# RE01_1500KB register map
Vendor: Renesas Electronics Corporation; Series: RE01_1500KB; File version: 1.20
CPU: CM0PLUS r0p1, little endian, MPU, no FPU, VTOR, 2 interrupt priority bits
Registers are 8-bit, read-write, reset 0x0 unless marked. A register's access mark holds for its fields unless they carry their own. Offsets are from the block's base; [hi:lo] are bit positions; {n}, {i} and the like mark numbered series.

## PMISC — Miscellaneous Port Control Register
Base 0x40040D00
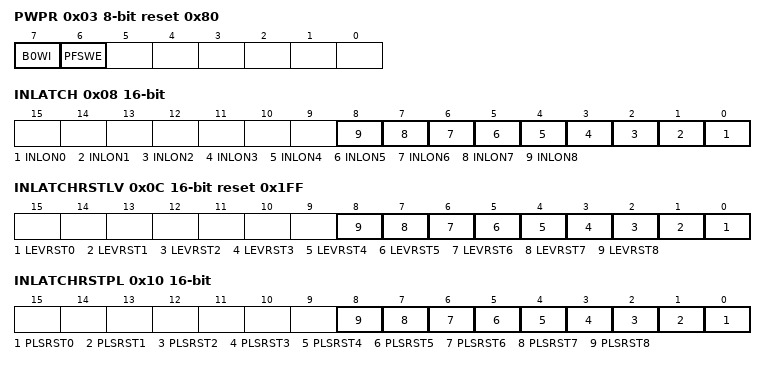
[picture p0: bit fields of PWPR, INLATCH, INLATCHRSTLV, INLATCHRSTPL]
0x03 PWPR reset 0x80 — Write-Protect Register
  [7] B0WI — PFSWE Bit Write Disable
    0=Writing to the PFSWE bit is enabled; 1=Writing to the PFSWE bit is disabled
  [6] PFSWE — PFS Register Write Enable
    0=Writing to the PFS register is disabled; 1=Writing to the PFS register is enabled
0x08 INLATCH 16-bit — Input PAD Latch Control Register
  [n] INLON{n} (n=0..8)
0x0C INLATCHRSTLV 16-bit reset 0x1FF — Input PAD Latch Level Reset Control Register
  [n] LEVRST{n} (n=0..8)
0x10 INLATCHRSTPL 16-bit — Input PAD Latch Pulse Reset Control Register
  [n] PLSRST{n} (n=0..8)

## POE — Port Output Enable Module for GPT
Base 0x40042000
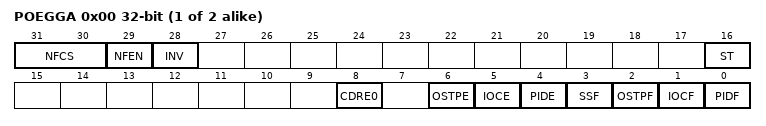
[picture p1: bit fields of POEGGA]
0x00 POEGG{x} (x=A,B; step 0x100) 32-bit — POEG Group {x} Setting Register
  [31:30] NFCS — Noise Filter Clock Select
    0=Sampling GTETRG pin input level for three times in every PCLKB; 1=Sampling GTETRG pin input level for three times in every PCLKB /8; 2=Sampling GTETRG pin input level for three times in every PCLKB /32; 3=Sampling GTETRG pin input level for three times in every PCLKB /128
  [29] NFEN — Noise Filter Enable
    0=Filtering noise disabled; 1=Filtering noise enabled
  [28] INV — GTETRG Input Reverse
    0=GTETRG Input; 1=GTETRG Input Reversed
  [16] ST ro — GTETRG Input Status Flag
    0=GTETRG input after filtering is 0; 1=GTETRG input after filtering is 1
  [8] CDRE0
  [6] OSTPE — Oscillation Stop Detection EnableNote: Can be modified only once after a reset.
    0=A output-disable request from the oscillation stop detection disabled; 1=A output-disable request from the oscillation stop detection enabled
  [5] IOCE — Real Time Overcurrent EnableNote: Can be modified only once after a reset.
    0=A output-disable request from GPT disable request or comparator interrupt disabled; 1=A output-disable request from GPT disable request or comparator interrupt enabled
  [4] PIDE — Port Input Detection EnableNote: Can be modified only once after a reset.
    0=A output-disable request from the GTETRG pins disabled; 1=A output-disable request from the GTETRG pins enabled
  [3] SSF — Software Stop Flag
    0=A output-disable request from software has not been generated; 1=A output-disable request from software has been generated
  [2] OSTPF — Oscillation Stop Detection Flag
    0=A output-disable request from the oscillation stop detection has not been generated; 1=A output-disable request from the oscillation stop detection has been generated
  [1] IOCF
  [0] PIDF — Port Input Detection Flag
    0=A output-disable request from the GTETRG pin has not been generated; 1=A output-disable request from the GTETRG pin has been generated

## PORT0 — Port 0 Control Registers
Base 0x40040000
Same registers: PORT1 0x40040020, PORT4 0x40040080, PORT5 0x400400A0, PORT6 0x400400C0, PORT7 0x400400E0, PORT8 0x40040100
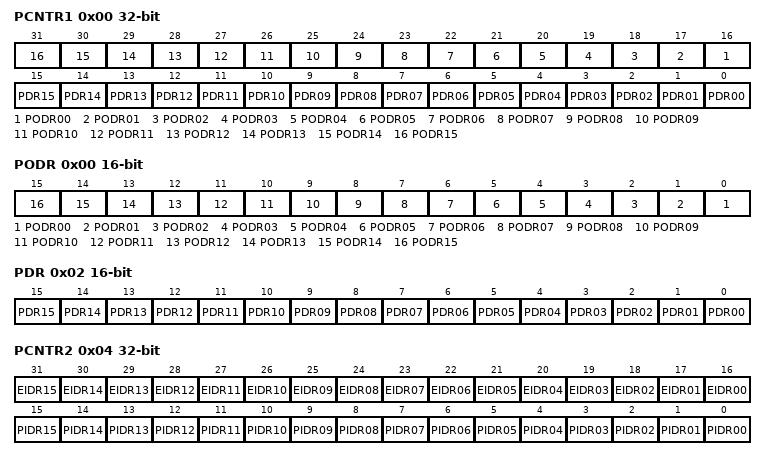
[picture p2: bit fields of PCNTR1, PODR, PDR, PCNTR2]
0x00 PCNTR1 32-bit — Port Control Register 1
  [n+16] PODR{n:02} (n=0..15), [n] PDR{n:02} (n=0..15)
0x00 PODR 16-bit (alternate view of PCNTR1) — Output data register
  [n] PODR{n:02} (n=0..15)
0x02 PDR 16-bit (alternate view of PCNTR1) — Direction register
  [n] PDR{n:02} (n=0..15)
0x04 PCNTR2 32-bit ro reset not defined — Port Control Register 2
  [n+16] EIDR{n:02} (n=0..15), [n] PIDR{n:02} (n=0..15)
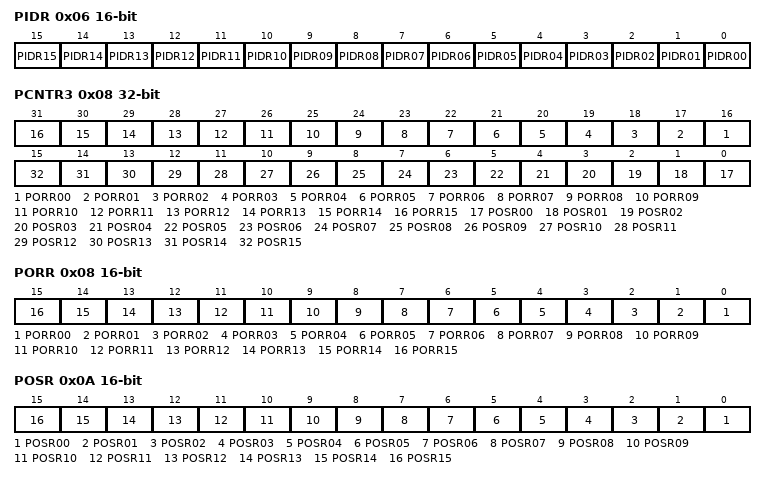
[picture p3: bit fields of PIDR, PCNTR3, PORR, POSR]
0x06 PIDR 16-bit ro reset not defined (alternate view of PCNTR2) — Input data register
  [n] PIDR{n:02} (n=0..15)
0x08 PCNTR3 32-bit wo — Port Control Register 3
  [n+16] PORR{n:02} (n=0..15), [n] POSR{n:02} (n=0..15)
0x08 PORR 16-bit wo (alternate view of PCNTR3) — Output reset register
  [n] PORR{n:02} (n=0..15)
0x0A POSR 16-bit wo (alternate view of PCNTR3) — Output set register
  [n] POSR{n:02} (n=0..15)

## PORT2 — Port 2 Control Registers
Base 0x40040040
Same registers: PORT3 0x40040060
Registers as PORT0; these are added or differ:
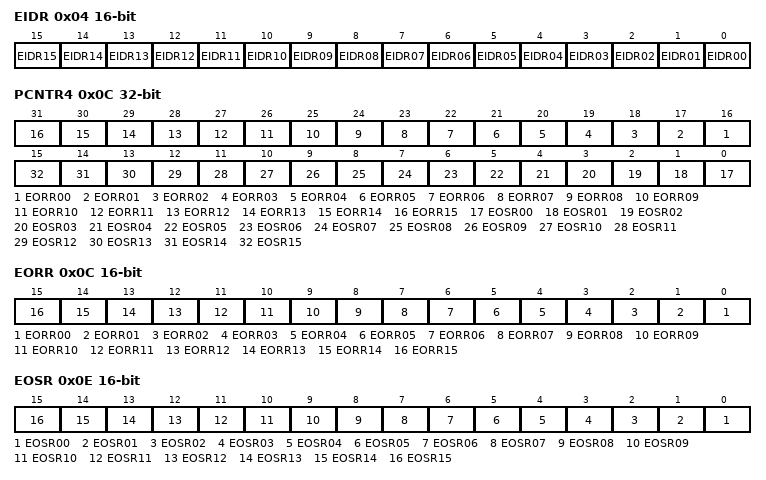
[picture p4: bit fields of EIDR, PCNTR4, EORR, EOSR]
0x04 EIDR 16-bit ro reset not defined (alternate view of PCNTR2) — Input data register
  [n] EIDR{n:02} (n=0..15)
0x0C PCNTR4 32-bit — Port Control Register 4
  [n+16] EORR{n:02} (n=0..15), [n] EOSR{n:02} (n=0..15)
0x0C EORR 16-bit (alternate view of PCNTR4) — Output reset register
  [n] EORR{n:02} (n=0..15)
0x0E EOSR 16-bit (alternate view of PCNTR4) — Output set register
  [n] EOSR{n:02} (n=0..15)
